# WS63 register map
File version: 1.0
CPU: other r0p0, little endian, MPU, FPU, 3 interrupt priority bits
Registers are 32-bit, read-write, reset 0x0 unless marked. A register's access mark holds for its fields unless they carry their own. Offsets are from the block's base; [hi:lo] are bit positions; {n}, {i} and the like mark numbered series.

## WDT — Watchdog timer (v151)
Base 0x40006000
0x00 WDT_LOCK — Watchdog lock register
  [31:0] wdt_lock wo — Write 0x5A5A5A5A to unlock, other values lock
0x04 WDT_LOAD — Watchdog load value
  [31:8] wdt_load — Load count value (24-bit, low 8 bits reserved)
0x08 WDT_RESTART — Watchdog restart register
  [31:0] wdt_restart wo — Write anything except 0x5A5A5A5A to restart counter
0x0C WDT_EOI — Watchdog interrupt clear (read to clear)
  [0] wdt_eoi ro — Read to clear watchdog interrupt
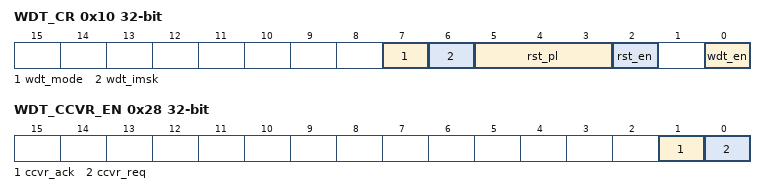
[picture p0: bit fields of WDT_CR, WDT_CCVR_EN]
0x10 WDT_CR — Watchdog control register
  [7] wdt_mode — Mode: 0=one interrupt then reset; 1=two interrupts then reset
    0=Mode1 (Single interrupt then reset); 1=Mode2 (Two interrupts then reset)
  [6] wdt_imsk — Interrupt mask: 0=unmasked; 1=masked
  [5:3] rst_pl — Reset pulse length: 000=2 clocks; up to 111=256 clocks
  [2] rst_en — Reset enable: 0=no reset on timeout; 1=reset on timeout
  [0] wdt_en — Watchdog enable: 0=disabled; 1=enabled
0x14 WDT_CNT — Watchdog current counter value
  [31:0] wdt_cnt ro — Current counter value
0x18 WDT_RAW_INTR — Watchdog raw interrupt status
  [0] wdt_raw_intr ro — Raw interrupt status
0x1C WDT_INTR — Watchdog interrupt status (masked)
  [0] wdt_intr ro — Interrupt status after mask
0x20 WDT_LPIF_STATE — Watchdog low power state
  [2:0] wdt_lpif_state ro — Low power interface state
0x24 WDT_STATUS — Watchdog status
  [0] wdt_status ro — Status: 0=busy; 1=free
0x28 WDT_CCVR_EN — Watchdog counter value request
  [1] ccvr_ack ro — Acknowledge: 1=counter value valid
  [0] ccvr_req wo — Write 1 to request current counter value

## RTC — Real-time clock (48-bit free-running counter, v100)
Base 0x57024000
0x00 RTC_LOAD_COUNT
  [31:0] load_count — Load count value (threshold for interrupt)
0x04 RTC_CURRENT_VALUE — RTC current count value
  [31:0] current_value ro — Current counter value
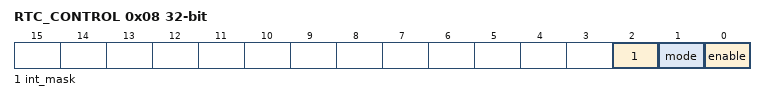
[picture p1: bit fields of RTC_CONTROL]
0x08 RTC_CONTROL
  [2] int_mask — Interrupt mask: 0=unmasked; 1=masked
  [1] mode — Mode: 0=free running; 1=periodic
  [0] enable — RTC enable
0x0C RTC_EOI — RTC end-of-interrupt (read to clear)
  [0] eoi ro — Read to clear RTC interrupt
0x10 RTC_INT_STATUS — RTC interrupt status
  [0] int_status ro — Interrupt status

## EFUSE — eFuse controller (OTP, v151)
Base 0x44008000
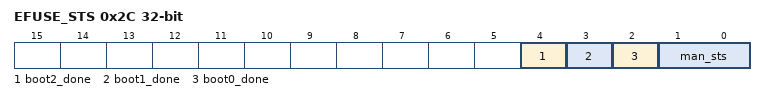
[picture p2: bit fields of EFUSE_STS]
0x2C EFUSE_STS — eFuse boot-done status register (base+0x2C). Read-only.
  [4] boot2_done ro — Boot2 done flag
  [3] boot1_done ro — Boot1 done flag
  [2] boot0_done ro — Boot0 done flag
  [1:0] man_sts ro — Manufacturing status
0x30 EFUSE_CTL_DATA — eFuse mode-select register (base+0x30). Write the 16-bit magic to arm an access: 0xA5A5 = program (write) mode, 0x5A5A = read mode.
  [15:0] efuse_wr_rd — Mode-select magic word (0xA5A5=write, 0x5A5A=read)
0x34 EFUSE_CLK_PERIOD — eFuse clock period register (base+0x34)
  [7:0] clk_period — Clock period in cycles (e.g. 0x29 @ 24MHz, 0x19 @ 40MHz)
0x3C EFUSE_AVDD_CTL — eFuse AVDD program-voltage switch (base+0x3C)
  [0] avdd_sw — AVDD switch: 1=enable program voltage, 0=disable
{0x800+4i} EFUSE_DATA[{i}] (i=0..127) — eFuse read/write data window (base+0x800), 128 words covering 256 bytes. Each 32-bit word packs two eFuse bytes: even byte address in [7:0], odd in [15:8]. Word index = byte_addr/2.
  [15:0] data — Two packed eFuse bytes (low byte=[7:0], high byte=[15:8])

## SYS_CTL0 — System Control 0 - reset status, clock control, PLL config
Base 0x40000000
0x08 RESET_COUNT ro
  [31:0] reset_count — Reset count value
0x14 HW_CTL ro — Hardware control register
  [0] refclk_freq_status — REFCLK frequency status: 0=40MHz; 1=24MHz
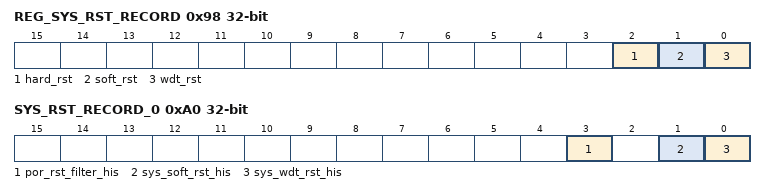
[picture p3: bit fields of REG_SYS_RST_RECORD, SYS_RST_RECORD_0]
0x98 REG_SYS_RST_RECORD — System reset record register
  [2] hard_rst — Hardware reset record
  [1] soft_rst — Software reset record
  [0] wdt_rst — Watchdog reset record
0xA0 SYS_RST_RECORD_0 ro — System reset history record 0
  [3] por_rst_filter_his — POR reset filter history
  [1] sys_soft_rst_his — Software reset history
  [0] sys_wdt_rst_his — WDT reset history
0xA4 SYS_DIAG_CLR_1 wo — System diagnostic clear 1
  [31:0] sys_diag_clr — Write to clear reset history bits
